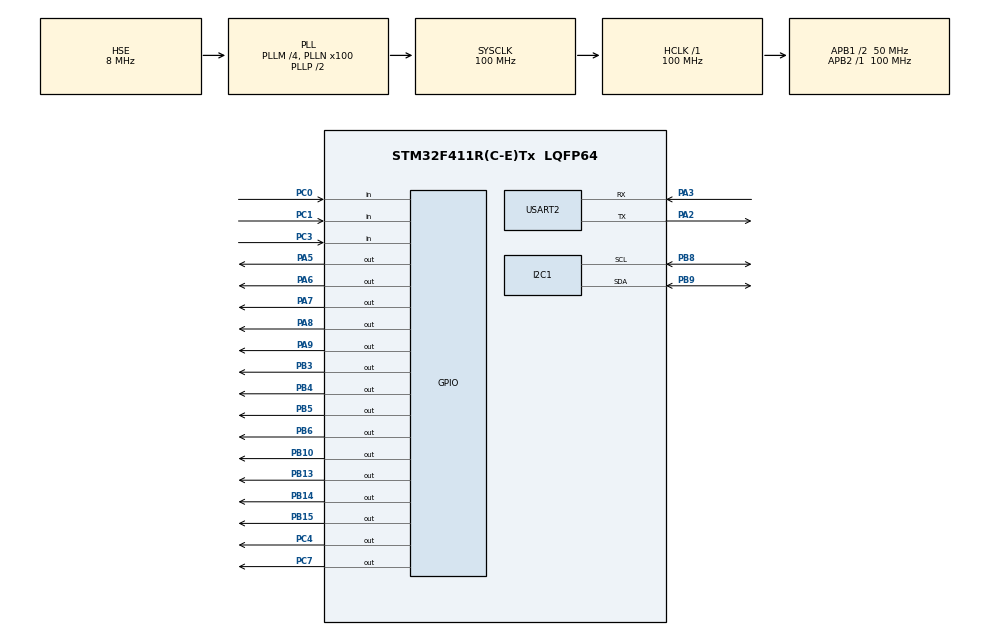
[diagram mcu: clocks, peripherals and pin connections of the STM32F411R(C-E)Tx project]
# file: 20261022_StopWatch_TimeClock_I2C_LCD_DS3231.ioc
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Mcu.Family=STM32F4
Mcu.Name=STM32F411R(C-E)Tx
Mcu.Package=LQFP64
NVIC.PriorityGroup=NVIC_PRIORITYGROUP_4
PA2.Mode=Asynchronous
PA2.Signal=USART2_TX
PA3.Mode=Asynchronous
PA3.Signal=USART2_RX
PA5.Signal=GPIO_Output
PA6.Signal=GPIO_Output
PA7.Signal=GPIO_Output
PA8.Signal=GPIO_Output
PA9.Signal=GPIO_Output
PB10.Signal=GPIO_Output
PB13.Signal=GPIO_Output
PB14.Signal=GPIO_Output
PB15.Signal=GPIO_Output
PB3.Signal=GPIO_Output
PB4.Signal=GPIO_Output
PB5.Signal=GPIO_Output
PB6.Signal=GPIO_Output
PB8.Mode=I2C
PB8.Signal=I2C1_SCL
PB9.Mode=I2C
PB9.Signal=I2C1_SDA
PC0.Signal=GPIO_Input
PC1.Signal=GPIO_Input
PC3.Signal=GPIO_Input
PC4.Signal=GPIO_Output
PC7.Signal=GPIO_Output
PH0\ -\ OSC_IN.Mode=HSE-External-Oscillator
PH0\ -\ OSC_IN.Signal=RCC_OSC_IN
PH1\ -\ OSC_OUT.Mode=HSE-External-Oscillator
PH1\ -\ OSC_OUT.Signal=RCC_OSC_OUT
ProjectManager.HeapSize=0x200
ProjectManager.StackSize=0x400
ProjectManager.TargetToolchain=STM32CubeIDE
RCC.48MHZClocksFreq_Value=50000000
RCC.AHBFreq_Value=100000000
RCC.APB1CLKDivider=RCC_HCLK_DIV2
RCC.APB1Freq_Value=50000000
RCC.APB1TimFreq_Value=100000000
RCC.APB2Freq_Value=100000000
RCC.APB2TimFreq_Value=100000000
RCC.CortexFreq_Value=100000000
RCC.HCLKFreq_Value=100000000
RCC.HSE_VALUE=8000000
RCC.HSI_VALUE=16000000
RCC.LSE_VALUE=32768
RCC.PLLM=4
RCC.PLLN=100
RCC.PLLSourceVirtual=RCC_PLLSOURCE_HSE
RCC.SYSCLKFreq_VALUE=100000000
RCC.SYSCLKSource=RCC_SYSCLKSOURCE_PLLCLK
RCC.VCOOutputFreq_Value=200000000
TIM4.Period=1000-1
TIM4.Prescaler=1000-1
USART2.VirtualMode=VM_ASYNC
VP_TIM2_VS_ClockSourceINT.Mode=Internal
VP_TIM3_VS_ClockSourceINT.Mode=Internal
VP_TIM4_VS_ClockSourceINT.Mode=Internal
board=custom

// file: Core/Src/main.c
/* USER CODE BEGIN Header */
/**
  ******************************************************************************
  * @file           : main.c
  * @brief          : Main program body
  ******************************************************************************
  * @attention
  *
  * Copyright (c) 2026 STMicroelectronics.
  * All rights reserved.
  *
  * This software is licensed under terms that can be found in the LICENSE file
  * in the root directory of this software component.
  * If no LICENSE file comes with this software, it is provided AS-IS.
  *
  ******************************************************************************
  */
/* USER CODE END Header */
#include "main.h"

/* USER CODE BEGIN Includes */
#include "ap/ap_main.h"
//#include "driver/DS3231/DS3231.h"
//#include <stdio.h>
/* USER CODE END Includes */

I2C_HandleTypeDef hi2c1;

TIM_HandleTypeDef htim2;
TIM_HandleTypeDef htim3;
TIM_HandleTypeDef htim4;

UART_HandleTypeDef huart2;

void SystemClock_Config(void);
static void MX_GPIO_Init(void);
static void MX_TIM2_Init(void);
static void MX_TIM4_Init(void);
static void MX_TIM3_Init(void);
static void MX_I2C1_Init(void);
static void MX_USART2_UART_Init(void);

/* USER CODE BEGIN 0 */
//int __io_putchar(int ch){
//
//	HAL_UART_Transmit(&huart2, (uint8_t *)&ch, 1, HAL_MAX_DELAY);
//	return ch;
//}

/* USER CODE END 0 */

int main(void)
{

  /* MCU Configuration--------------------------------------------------------*/

  /* Reset of all peripherals, Initializes the Flash interface and the Systick. */
  HAL_Init();

  /* Configure the system clock */
  SystemClock_Config();

  /* Initialize all configured peripherals */
  MX_GPIO_Init();
  MX_TIM2_Init();
  MX_TIM4_Init();
  MX_TIM3_Init();
  MX_I2C1_Init();
  MX_USART2_UART_Init();
  /* USER CODE BEGIN 2 */
//  ds3231_init(&hi2c1);
//  ds3231_setDateTime(&rtc_datetime);

//  char *str_day[7] = {"SUN", "MON", "TUE", "WED", "THU", "FRI", "SAT"};

  /* USER CODE END 2 */

  /* Infinite loop */
  /* USER CODE BEGIN WHILE */
  while (1)
  {
	  ap_main();
//	  ds3231_getDate(&rtc_date);
//	  ds3231_getTime(&rtc_time);
//	  printf("20%02d-%02d-%02d %s\n", rtc_date.year, rtc_date.month, rtc_date.date, str_day[rtc_date.day]);
//	  printf("%02d:%02d:%02d\n\n", rtc_time.hour, rtc_time.min, rtc_time.sec);
//	  HAL_Delay(1000);
    /* USER CODE END WHILE */

  }
}

void SystemClock_Config(void)
{
  RCC_OscInitTypeDef RCC_OscInitStruct = {0};
  RCC_ClkInitTypeDef RCC_ClkInitStruct = {0};

  /** Configure the main internal regulator output voltage
  */
  __HAL_RCC_PWR_CLK_ENABLE();
  __HAL_PWR_VOLTAGESCALING_CONFIG(PWR_REGULATOR_VOLTAGE_SCALE1);

  /** Initializes the RCC Oscillators according to the specified parameters
  * in the RCC_OscInitTypeDef structure.
  */
  RCC_OscInitStruct.OscillatorType = RCC_OSCILLATORTYPE_HSE;
  RCC_OscInitStruct.HSEState = RCC_HSE_ON;
  RCC_OscInitStruct.PLL.PLLState = RCC_PLL_ON;
  RCC_OscInitStruct.PLL.PLLSource = RCC_PLLSOURCE_HSE;
  RCC_OscInitStruct.PLL.PLLM = 4;
  RCC_OscInitStruct.PLL.PLLN = 100;
  RCC_OscInitStruct.PLL.PLLP = RCC_PLLP_DIV2;
  RCC_OscInitStruct.PLL.PLLQ = 4;
  if (HAL_RCC_OscConfig(&RCC_OscInitStruct) != HAL_OK)
  {
    Error_Handler();
  }

  /** Initializes the CPU, AHB and APB buses clocks
  */
  RCC_ClkInitStruct.ClockType = RCC_CLOCKTYPE_HCLK|RCC_CLOCKTYPE_SYSCLK
                              |RCC_CLOCKTYPE_PCLK1|RCC_CLOCKTYPE_PCLK2;
  RCC_ClkInitStruct.SYSCLKSource = RCC_SYSCLKSOURCE_PLLCLK;
  RCC_ClkInitStruct.AHBCLKDivider = RCC_SYSCLK_DIV1;
  RCC_ClkInitStruct.APB1CLKDivider = RCC_HCLK_DIV2;
  RCC_ClkInitStruct.APB2CLKDivider = RCC_HCLK_DIV1;

  if (HAL_RCC_ClockConfig(&RCC_ClkInitStruct, FLASH_LATENCY_3) != HAL_OK)
  {
    Error_Handler();
  }
}

static void MX_I2C1_Init(void)
{

  hi2c1.Instance = I2C1;
  hi2c1.Init.ClockSpeed = 100000;
  hi2c1.Init.DutyCycle = I2C_DUTYCYCLE_2;
  hi2c1.Init.OwnAddress1 = 0;
  hi2c1.Init.AddressingMode = I2C_ADDRESSINGMODE_7BIT;
  hi2c1.Init.DualAddressMode = I2C_DUALADDRESS_DISABLE;
  hi2c1.Init.OwnAddress2 = 0;
  hi2c1.Init.GeneralCallMode = I2C_GENERALCALL_DISABLE;
  hi2c1.Init.NoStretchMode = I2C_NOSTRETCH_DISABLE;
  if (HAL_I2C_Init(&hi2c1) != HAL_OK)
  {
    Error_Handler();
  }

}

static void MX_TIM2_Init(void)
{

  TIM_ClockConfigTypeDef sClockSourceConfig = {0};
  TIM_MasterConfigTypeDef sMasterConfig = {0};

  htim2.Instance = TIM2;
  htim2.Init.Prescaler = 0;
  htim2.Init.CounterMode = TIM_COUNTERMODE_UP;
  htim2.Init.Period = 4294967295;
  htim2.Init.ClockDivision = TIM_CLOCKDIVISION_DIV1;
  htim2.Init.AutoReloadPreload = TIM_AUTORELOAD_PRELOAD_DISABLE;
  if (HAL_TIM_Base_Init(&htim2) != HAL_OK)
  {
    Error_Handler();
  }
  sClockSourceConfig.ClockSource = TIM_CLOCKSOURCE_INTERNAL;
  if (HAL_TIM_ConfigClockSource(&htim2, &sClockSourceConfig) != HAL_OK)
  {
    Error_Handler();
  }
  sMasterConfig.MasterOutputTrigger = TIM_TRGO_RESET;
  sMasterConfig.MasterSlaveMode = TIM_MASTERSLAVEMODE_DISABLE;
  if (HAL_TIMEx_MasterConfigSynchronization(&htim2, &sMasterConfig) != HAL_OK)
  {
    Error_Handler();
  }

}

static void MX_TIM3_Init(void)
{

  TIM_ClockConfigTypeDef sClockSourceConfig = {0};
  TIM_MasterConfigTypeDef sMasterConfig = {0};

  htim3.Instance = TIM3;
  htim3.Init.Prescaler = 0;
  htim3.Init.CounterMode = TIM_COUNTERMODE_UP;
  htim3.Init.Period = 65535;
  htim3.Init.ClockDivision = TIM_CLOCKDIVISION_DIV1;
  htim3.Init.AutoReloadPreload = TIM_AUTORELOAD_PRELOAD_DISABLE;
  if (HAL_TIM_Base_Init(&htim3) != HAL_OK)
  {
    Error_Handler();
  }
  sClockSourceConfig.ClockSource = TIM_CLOCKSOURCE_INTERNAL;
  if (HAL_TIM_ConfigClockSource(&htim3, &sClockSourceConfig) != HAL_OK)
  {
    Error_Handler();
  }
  sMasterConfig.MasterOutputTrigger = TIM_TRGO_RESET;
  sMasterConfig.MasterSlaveMode = TIM_MASTERSLAVEMODE_DISABLE;
  if (HAL_TIMEx_MasterConfigSynchronization(&htim3, &sMasterConfig) != HAL_OK)
  {
    Error_Handler();
  }

}

static void MX_TIM4_Init(void)
{

  TIM_ClockConfigTypeDef sClockSourceConfig = {0};
  TIM_MasterConfigTypeDef sMasterConfig = {0};

  htim4.Instance = TIM4;
  htim4.Init.Prescaler = 1000-1;
  htim4.Init.CounterMode = TIM_COUNTERMODE_UP;
  htim4.Init.Period = 1000-1;
  htim4.Init.ClockDivision = TIM_CLOCKDIVISION_DIV1;
  htim4.Init.AutoReloadPreload = TIM_AUTORELOAD_PRELOAD_DISABLE;
  if (HAL_TIM_Base_Init(&htim4) != HAL_OK)
  {
    Error_Handler();
  }
  sClockSourceConfig.ClockSource = TIM_CLOCKSOURCE_INTERNAL;
  if (HAL_TIM_ConfigClockSource(&htim4, &sClockSourceConfig) != HAL_OK)
  {
    Error_Handler();
  }
  sMasterConfig.MasterOutputTrigger = TIM_TRGO_RESET;
  sMasterConfig.MasterSlaveMode = TIM_MASTERSLAVEMODE_DISABLE;
  if (HAL_TIMEx_MasterConfigSynchronization(&htim4, &sMasterConfig) != HAL_OK)
  {
    Error_Handler();
  }

}

static void MX_USART2_UART_Init(void)
{

  huart2.Instance = USART2;
  huart2.Init.BaudRate = 115200;
  huart2.Init.WordLength = UART_WORDLENGTH_8B;
  huart2.Init.StopBits = UART_STOPBITS_1;
  huart2.Init.Parity = UART_PARITY_NONE;
  huart2.Init.Mode = UART_MODE_TX_RX;
  huart2.Init.HwFlowCtl = UART_HWCONTROL_NONE;
  huart2.Init.OverSampling = UART_OVERSAMPLING_16;
  if (HAL_UART_Init(&huart2) != HAL_OK)
  {
    Error_Handler();
  }

}

static void MX_GPIO_Init(void)
{
  GPIO_InitTypeDef GPIO_InitStruct = {0};

  /* GPIO Ports Clock Enable */
  __HAL_RCC_GPIOH_CLK_ENABLE();
  __HAL_RCC_GPIOC_CLK_ENABLE();
  __HAL_RCC_GPIOA_CLK_ENABLE();
  __HAL_RCC_GPIOB_CLK_ENABLE();

  /*Configure GPIO pin Output Level */
  HAL_GPIO_WritePin(GPIOA, GPIO_PIN_5|GPIO_PIN_6|GPIO_PIN_7|GPIO_PIN_8
                          |GPIO_PIN_9, GPIO_PIN_RESET);

  /*Configure GPIO pin Output Level */
  HAL_GPIO_WritePin(GPIOC, GPIO_PIN_4|GPIO_PIN_7, GPIO_PIN_RESET);

  /*Configure GPIO pin Output Level */
  HAL_GPIO_WritePin(GPIOB, GPIO_PIN_10|GPIO_PIN_13|GPIO_PIN_14|GPIO_PIN_15
                          |GPIO_PIN_3|GPIO_PIN_4|GPIO_PIN_5|GPIO_PIN_6, GPIO_PIN_RESET);

  /*Configure GPIO pins : PC0 PC1 PC3 */
  GPIO_InitStruct.Pin = GPIO_PIN_0|GPIO_PIN_1|GPIO_PIN_3;
  GPIO_InitStruct.Mode = GPIO_MODE_INPUT;
  GPIO_InitStruct.Pull = GPIO_NOPULL;
  HAL_GPIO_Init(GPIOC, &GPIO_InitStruct);

  /*Configure GPIO pins : PA5 PA6 PA7 PA8
                           PA9 */
  GPIO_InitStruct.Pin = GPIO_PIN_5|GPIO_PIN_6|GPIO_PIN_7|GPIO_PIN_8
                          |GPIO_PIN_9;
  GPIO_InitStruct.Mode = GPIO_MODE_OUTPUT_PP;
  GPIO_InitStruct.Pull = GPIO_NOPULL;
  GPIO_InitStruct.Speed = GPIO_SPEED_FREQ_LOW;
  HAL_GPIO_Init(GPIOA, &GPIO_InitStruct);

  /*Configure GPIO pins : PC4 PC7 */
  GPIO_InitStruct.Pin = GPIO_PIN_4|GPIO_PIN_7;
  GPIO_InitStruct.Mode = GPIO_MODE_OUTPUT_PP;
  GPIO_InitStruct.Pull = GPIO_NOPULL;
  GPIO_InitStruct.Speed = GPIO_SPEED_FREQ_LOW;
  HAL_GPIO_Init(GPIOC, &GPIO_InitStruct);

  /*Configure GPIO pins : PB10 PB13 PB14 PB15
                           PB3 PB4 PB5 PB6 */
  GPIO_InitStruct.Pin = GPIO_PIN_10|GPIO_PIN_13|GPIO_PIN_14|GPIO_PIN_15
                          |GPIO_PIN_3|GPIO_PIN_4|GPIO_PIN_5|GPIO_PIN_6;
  GPIO_InitStruct.Mode = GPIO_MODE_OUTPUT_PP;
  GPIO_InitStruct.Pull = GPIO_NOPULL;
  GPIO_InitStruct.Speed = GPIO_SPEED_FREQ_LOW;
  HAL_GPIO_Init(GPIOB, &GPIO_InitStruct);

}

void Error_Handler(void)
{
  __disable_irq();
  while (1)
  {
  }
}
